# ioam3358 register map
Registers are 32-bit, access not given, no defined reset value unless marked. A register's access mark holds for its fields unless they carry their own. Addresses are absolute; registers are grouped by the start of their names; [hi:lo] are bit positions.

## UART1
0x48022000 UART1_DLL 8-bit
0x48022000 UART1_RHR 8-bit
0x48022000 UART1_THR 8-bit
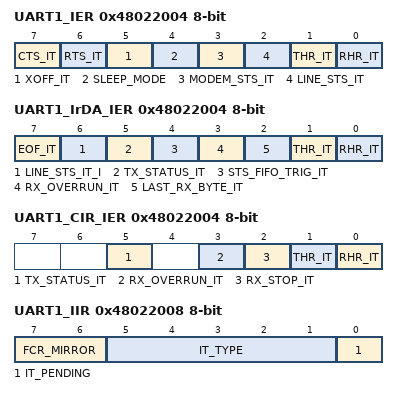
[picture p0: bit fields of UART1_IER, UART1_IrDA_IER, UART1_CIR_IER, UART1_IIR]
0x48022004 UART1_IER 8-bit
  [7] CTS_IT, [6] RTS_IT, [5] XOFF_IT, [4] SLEEP_MODE, [3] MODEM_STS_IT, [2] LINE_STS_IT, [1] THR_IT, [0] RHR_IT
0x48022004 UART1_DLH 8-bit
0x48022004 UART1_IrDA_IER 8-bit
  [7] EOF_IT, [6] LINE_STS_IT_I, [5] TX_STATUS_IT, [4] STS_FIFO_TRIG_IT, [3] RX_OVERRUN_IT, [2] LAST_RX_BYTE_IT, [1] THR_IT, [0] RHR_IT
0x48022004 UART1_CIR_IER 8-bit
  [5] TX_STATUS_IT, [3] RX_OVERRUN_IT, [2] RX_STOP_IT, [1] THR_IT, [0] RHR_IT
0x48022008 UART1_IIR 8-bit
  [7:6] FCR_MIRROR, [5:1] IT_TYPE, [0] IT_PENDING
0x48022008 UART1_FCR 8-bit
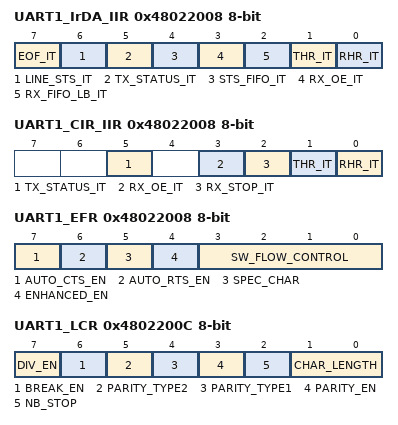
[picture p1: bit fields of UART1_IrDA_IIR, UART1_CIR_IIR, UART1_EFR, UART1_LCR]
0x48022008 UART1_IrDA_IIR 8-bit
  [7] EOF_IT, [6] LINE_STS_IT, [5] TX_STATUS_IT, [4] STS_FIFO_IT, [3] RX_OE_IT, [2] RX_FIFO_LB_IT, [1] THR_IT, [0] RHR_IT
0x48022008 UART1_CIR_IIR 8-bit
  [5] TX_STATUS_IT, [3] RX_OE_IT, [2] RX_STOP_IT, [1] THR_IT, [0] RHR_IT
0x48022008 UART1_EFR 8-bit
  [7] AUTO_CTS_EN, [6] AUTO_RTS_EN, [5] SPEC_CHAR, [4] ENHANCED_EN, [3:0] SW_FLOW_CONTROL
0x4802200C UART1_LCR 8-bit
  [7] DIV_EN, [6] BREAK_EN, [5] PARITY_TYPE2, [4] PARITY_TYPE1, [3] PARITY_EN, [2] NB_STOP, [1:0] CHAR_LENGTH
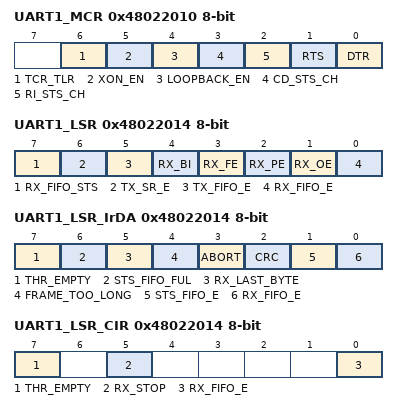
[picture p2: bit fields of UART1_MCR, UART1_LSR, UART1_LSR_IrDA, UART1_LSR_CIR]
0x48022010 UART1_MCR 8-bit
  [6] TCR_TLR, [5] XON_EN, [4] LOOPBACK_EN, [3] CD_STS_CH, [2] RI_STS_CH, [1] RTS, [0] DTR
0x48022010 UART1_XON1_ADDR1 8-bit
0x48022014 UART1_LSR 8-bit
  [7] RX_FIFO_STS, [6] TX_SR_E, [5] TX_FIFO_E, [4] RX_BI, [3] RX_FE, [2] RX_PE, [1] RX_OE, [0] RX_FIFO_E
0x48022014 UART1_XON2_ADDR2 8-bit
0x48022014 UART1_LSR_IrDA 8-bit
  [7] THR_EMPTY, [6] STS_FIFO_FUL, [5] RX_LAST_BYTE, [4] FRAME_TOO_LONG, [3] ABORT, [2] CRC, [1] STS_FIFO_E, [0] RX_FIFO_E
0x48022014 UART1_LSR_CIR 8-bit
  [7] THR_EMPTY, [5] RX_STOP, [0] RX_FIFO_E
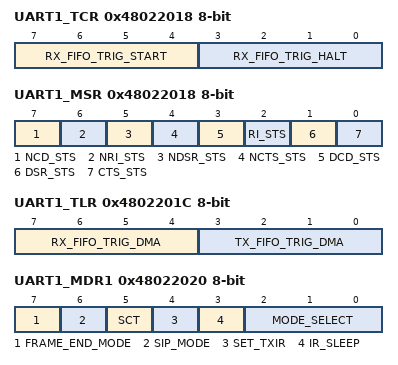
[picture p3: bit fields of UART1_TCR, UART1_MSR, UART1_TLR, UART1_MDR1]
0x48022018 UART1_TCR 8-bit
  [7:4] RX_FIFO_TRIG_START, [3:0] RX_FIFO_TRIG_HALT
0x48022018 UART1_XOFF1 8-bit
0x48022018 UART1_MSR 8-bit
  [7] NCD_STS, [6] NRI_STS, [5] NDSR_STS, [4] NCTS_STS, [3] DCD_STS, [2] RI_STS, [1] DSR_STS, [0] CTS_STS
0x4802201C UART1_TLR 8-bit
  [7:4] RX_FIFO_TRIG_DMA, [3:0] TX_FIFO_TRIG_DMA
0x4802201C UART1_SPR 8-bit
0x4802201C UART1_XOFF2 8-bit
0x48022020 UART1_MDR1 8-bit
  [7] FRAME_END_MODE, [6] SIP_MODE, [5] SCT, [4] SET_TXIR, [3] IR_SLEEP, [2:0] MODE_SELECT
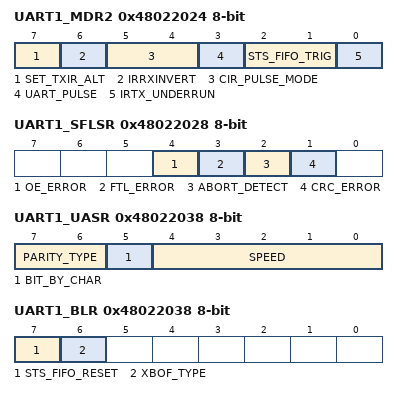
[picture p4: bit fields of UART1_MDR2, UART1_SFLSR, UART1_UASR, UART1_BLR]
0x48022024 UART1_MDR2 8-bit
  [7] SET_TXIR_ALT, [6] IRRXINVERT, [5:4] CIR_PULSE_MODE, [3] UART_PULSE, [2:1] STS_FIFO_TRIG, [0] IRTX_UNDERRUN
0x48022028 UART1_SFLSR 8-bit
  [4] OE_ERROR, [3] FTL_ERROR, [2] ABORT_DETECT, [1] CRC_ERROR
0x48022028 UART1_TXFLL 8-bit
0x4802202C UART1_TXFLH 8-bit
  [4:0] TXFLH
0x4802202C UART1_RESUME 8-bit
0x48022030 UART1_SFREGL 8-bit
0x48022030 UART1_RXFLL 8-bit
0x48022034 UART1_SFREGH 8-bit
  [3:0] SFREGH
0x48022034 UART1_RXFLH 8-bit
  [3:0] RXFLH
0x48022038 UART1_UASR 8-bit
  [7:6] PARITY_TYPE, [5] BIT_BY_CHAR, [4:0] SPEED
0x48022038 UART1_BLR 8-bit
  [7] STS_FIFO_RESET, [6] XBOF_TYPE
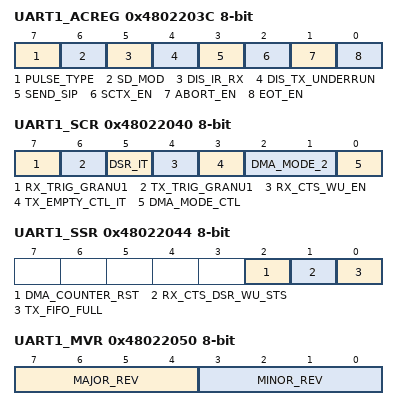
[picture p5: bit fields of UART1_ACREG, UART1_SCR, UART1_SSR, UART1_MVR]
0x4802203C UART1_ACREG 8-bit
  [7] PULSE_TYPE, [6] SD_MOD, [5] DIS_IR_RX, [4] DIS_TX_UNDERRUN, [3] SEND_SIP, [2] SCTX_EN, [1] ABORT_EN, [0] EOT_EN
0x48022040 UART1_SCR 8-bit
  [7] RX_TRIG_GRANU1, [6] TX_TRIG_GRANU1, [5] DSR_IT, [4] RX_CTS_WU_EN, [3] TX_EMPTY_CTL_IT, [2:1] DMA_MODE_2, [0] DMA_MODE_CTL
0x48022044 UART1_SSR 8-bit
  [2] DMA_COUNTER_RST, [1] RX_CTS_DSR_WU_STS, [0] TX_FIFO_FULL
0x48022048 UART1_EBLR 8-bit
0x48022050 UART1_MVR 8-bit
  [7:4] MAJOR_REV, [3:0] MINOR_REV
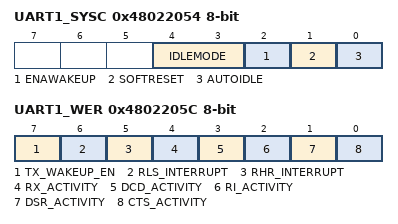
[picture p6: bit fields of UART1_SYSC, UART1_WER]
0x48022054 UART1_SYSC 8-bit
  [4:3] IDLEMODE, [2] ENAWAKEUP, [1] SOFTRESET, [0] AUTOIDLE
0x48022058 UART1_SYSS 8-bit
  [0] RESETDONE
0x4802205C UART1_WER 8-bit
  [7] TX_WAKEUP_EN, [6] RLS_INTERRUPT, [5] RHR_INTERRUPT, [4] RX_ACTIVITY, [3] DCD_ACTIVITY, [2] RI_ACTIVITY, [1] DSR_ACTIVITY, [0] CTS_ACTIVITY
0x48022060 UART1_CFPS 8-bit

## UART2
0x48024000 UART2_DLL 8-bit
0x48024000 UART2_RHR 8-bit
0x48024000 UART2_THR 8-bit
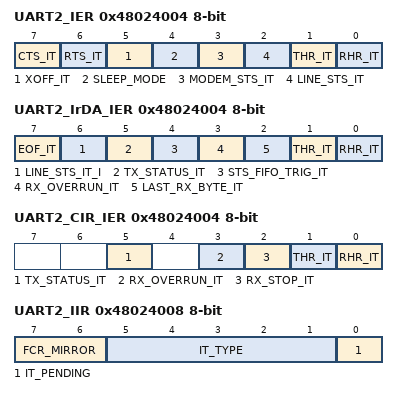
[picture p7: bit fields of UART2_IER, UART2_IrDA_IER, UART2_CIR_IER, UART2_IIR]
0x48024004 UART2_IER 8-bit
  [7] CTS_IT, [6] RTS_IT, [5] XOFF_IT, [4] SLEEP_MODE, [3] MODEM_STS_IT, [2] LINE_STS_IT, [1] THR_IT, [0] RHR_IT
0x48024004 UART2_DLH 8-bit
0x48024004 UART2_IrDA_IER 8-bit
  [7] EOF_IT, [6] LINE_STS_IT_I, [5] TX_STATUS_IT, [4] STS_FIFO_TRIG_IT, [3] RX_OVERRUN_IT, [2] LAST_RX_BYTE_IT, [1] THR_IT, [0] RHR_IT
0x48024004 UART2_CIR_IER 8-bit
  [5] TX_STATUS_IT, [3] RX_OVERRUN_IT, [2] RX_STOP_IT, [1] THR_IT, [0] RHR_IT
0x48024008 UART2_IIR 8-bit
  [7:6] FCR_MIRROR, [5:1] IT_TYPE, [0] IT_PENDING
0x48024008 UART2_FCR 8-bit
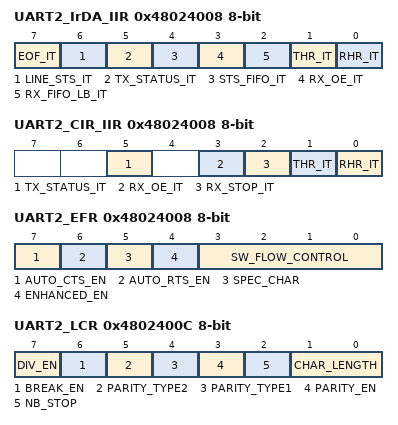
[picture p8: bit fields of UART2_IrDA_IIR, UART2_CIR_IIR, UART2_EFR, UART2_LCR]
0x48024008 UART2_IrDA_IIR 8-bit
  [7] EOF_IT, [6] LINE_STS_IT, [5] TX_STATUS_IT, [4] STS_FIFO_IT, [3] RX_OE_IT, [2] RX_FIFO_LB_IT, [1] THR_IT, [0] RHR_IT
0x48024008 UART2_CIR_IIR 8-bit
  [5] TX_STATUS_IT, [3] RX_OE_IT, [2] RX_STOP_IT, [1] THR_IT, [0] RHR_IT
0x48024008 UART2_EFR 8-bit
  [7] AUTO_CTS_EN, [6] AUTO_RTS_EN, [5] SPEC_CHAR, [4] ENHANCED_EN, [3:0] SW_FLOW_CONTROL
0x4802400C UART2_LCR 8-bit
  [7] DIV_EN, [6] BREAK_EN, [5] PARITY_TYPE2, [4] PARITY_TYPE1, [3] PARITY_EN, [2] NB_STOP, [1:0] CHAR_LENGTH
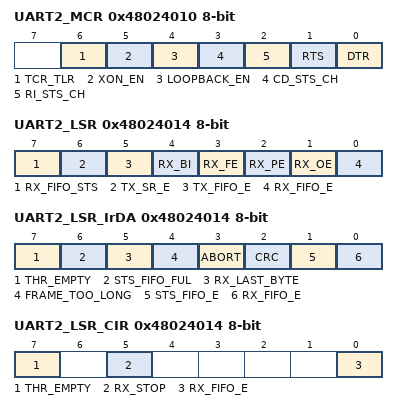
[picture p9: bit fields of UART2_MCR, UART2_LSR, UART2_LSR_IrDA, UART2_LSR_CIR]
0x48024010 UART2_MCR 8-bit
  [6] TCR_TLR, [5] XON_EN, [4] LOOPBACK_EN, [3] CD_STS_CH, [2] RI_STS_CH, [1] RTS, [0] DTR
0x48024010 UART2_XON1_ADDR1 8-bit
0x48024014 UART2_LSR 8-bit
  [7] RX_FIFO_STS, [6] TX_SR_E, [5] TX_FIFO_E, [4] RX_BI, [3] RX_FE, [2] RX_PE, [1] RX_OE, [0] RX_FIFO_E
0x48024014 UART2_XON2_ADDR2 8-bit
0x48024014 UART2_LSR_IrDA 8-bit
  [7] THR_EMPTY, [6] STS_FIFO_FUL, [5] RX_LAST_BYTE, [4] FRAME_TOO_LONG, [3] ABORT, [2] CRC, [1] STS_FIFO_E, [0] RX_FIFO_E
0x48024014 UART2_LSR_CIR 8-bit
  [7] THR_EMPTY, [5] RX_STOP, [0] RX_FIFO_E
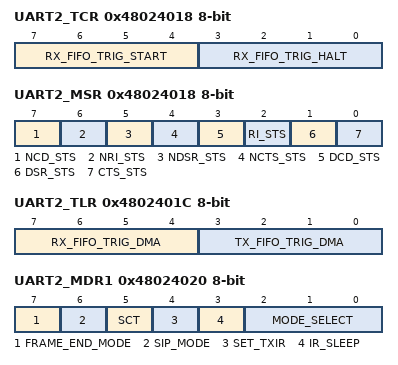
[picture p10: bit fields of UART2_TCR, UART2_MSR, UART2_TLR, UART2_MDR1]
0x48024018 UART2_TCR 8-bit
  [7:4] RX_FIFO_TRIG_START, [3:0] RX_FIFO_TRIG_HALT
0x48024018 UART2_XOFF1 8-bit
0x48024018 UART2_MSR 8-bit
  [7] NCD_STS, [6] NRI_STS, [5] NDSR_STS, [4] NCTS_STS, [3] DCD_STS, [2] RI_STS, [1] DSR_STS, [0] CTS_STS
0x4802401C UART2_TLR 8-bit
  [7:4] RX_FIFO_TRIG_DMA, [3:0] TX_FIFO_TRIG_DMA
0x4802401C UART2_SPR 8-bit
0x4802401C UART2_XOFF2 8-bit
0x48024020 UART2_MDR1 8-bit
  [7] FRAME_END_MODE, [6] SIP_MODE, [5] SCT, [4] SET_TXIR, [3] IR_SLEEP, [2:0] MODE_SELECT
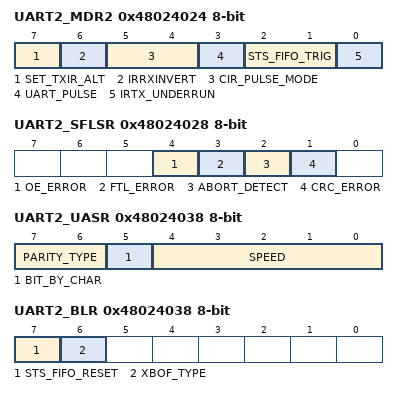
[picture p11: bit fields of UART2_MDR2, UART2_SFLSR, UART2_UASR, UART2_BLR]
0x48024024 UART2_MDR2 8-bit
  [7] SET_TXIR_ALT, [6] IRRXINVERT, [5:4] CIR_PULSE_MODE, [3] UART_PULSE, [2:1] STS_FIFO_TRIG, [0] IRTX_UNDERRUN
0x48024028 UART2_SFLSR 8-bit
  [4] OE_ERROR, [3] FTL_ERROR, [2] ABORT_DETECT, [1] CRC_ERROR
0x48024028 UART2_TXFLL 8-bit
0x4802402C UART2_TXFLH 8-bit
  [4:0] TXFLH
0x4802402C UART2_RESUME 8-bit
0x48024030 UART2_SFREGL 8-bit
0x48024030 UART2_RXFLL 8-bit
0x48024034 UART2_SFREGH 8-bit
  [3:0] SFREGH
0x48024034 UART2_RXFLH 8-bit
  [3:0] RXFLH
0x48024038 UART2_UASR 8-bit
  [7:6] PARITY_TYPE, [5] BIT_BY_CHAR, [4:0] SPEED
0x48024038 UART2_BLR 8-bit
  [7] STS_FIFO_RESET, [6] XBOF_TYPE
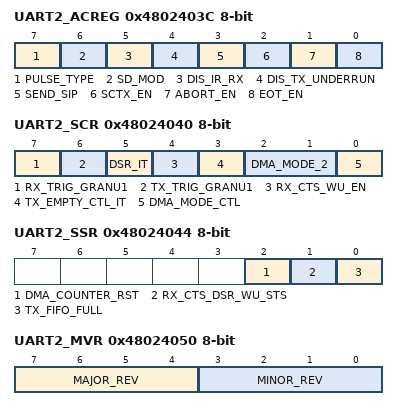
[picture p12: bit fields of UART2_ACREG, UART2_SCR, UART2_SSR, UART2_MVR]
0x4802403C UART2_ACREG 8-bit
  [7] PULSE_TYPE, [6] SD_MOD, [5] DIS_IR_RX, [4] DIS_TX_UNDERRUN, [3] SEND_SIP, [2] SCTX_EN, [1] ABORT_EN, [0] EOT_EN
0x48024040 UART2_SCR 8-bit
  [7] RX_TRIG_GRANU1, [6] TX_TRIG_GRANU1, [5] DSR_IT, [4] RX_CTS_WU_EN, [3] TX_EMPTY_CTL_IT, [2:1] DMA_MODE_2, [0] DMA_MODE_CTL
0x48024044 UART2_SSR 8-bit
  [2] DMA_COUNTER_RST, [1] RX_CTS_DSR_WU_STS, [0] TX_FIFO_FULL
0x48024048 UART2_EBLR 8-bit
0x48024050 UART2_MVR 8-bit
  [7:4] MAJOR_REV, [3:0] MINOR_REV
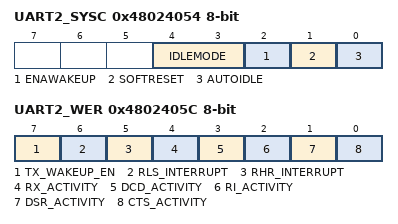
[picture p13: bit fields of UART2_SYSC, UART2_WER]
0x48024054 UART2_SYSC 8-bit
  [4:3] IDLEMODE, [2] ENAWAKEUP, [1] SOFTRESET, [0] AUTOIDLE
0x48024058 UART2_SYSS 8-bit
  [0] RESETDONE
0x4802405C UART2_WER 8-bit
  [7] TX_WAKEUP_EN, [6] RLS_INTERRUPT, [5] RHR_INTERRUPT, [4] RX_ACTIVITY, [3] DCD_ACTIVITY, [2] RI_ACTIVITY, [1] DSR_ACTIVITY, [0] CTS_ACTIVITY
0x48024060 UART2_CFPS 8-bit
